# RasbperryPi register map
File version: 1
Registers are 32-bit, read-write, reset 0x0 unless marked. A register's access mark holds for its fields unless they carry their own. Offsets are from the block's base; [hi:lo] are bit positions; {n}, {i} and the like mark numbered series; 'fields as' and 'values as' point back to an identical list.

## SMI — Derived from smi.h apb_id: 0x534D4958
Base 0x7E600000
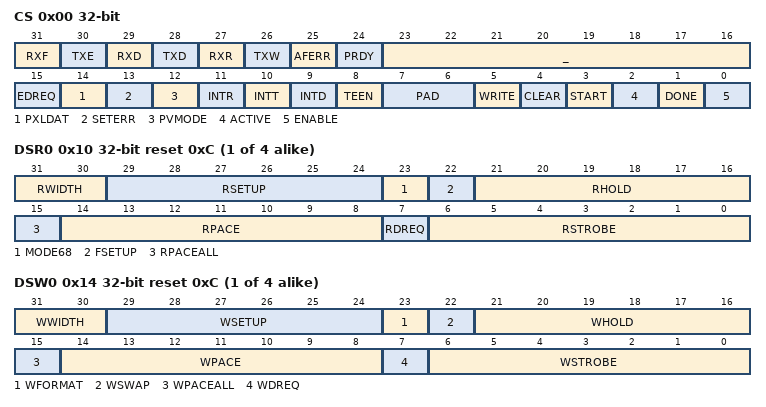
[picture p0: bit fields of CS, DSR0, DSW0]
0x00 CS reset not defined
  [31] RXF, [30] TXE, [29] RXD, [28] TXD, [27] RXR, [26] TXW, [25] AFERR, [24] PRDY, [23:16] _, [15] EDREQ, [14] PXLDAT, [13] SETERR, [12] PVMODE, [11] INTR, [10] INTT, [9] INTD, [8] TEEN, [7:6] PAD, [5] WRITE, [4] CLEAR, [3] START, [2] ACTIVE, [1] DONE, [0] ENABLE
0x04 L
  [31:0] data
0x08 A 10-bit
  [9:8] DEVICE, [7:6] _, [5:0] ADDR
0x0C D
  [31:0] data
{0x10+8i} DSR{i} reset 0xC (i=0..3)
  [31:30] RWIDTH, [29:24] RSETUP, [23] MODE68, [22] FSETUP, [21:16] RHOLD, [15] RPACEALL, [14:8] RPACE, [7] RDREQ, [6:0] RSTROBE
{0x14+8i} DSW{i} reset 0xC (i=0..3)
  [31:30] WWIDTH, [29:24] WSETUP, [23] WFORMAT, [22] WSWAP, [21:16] WHOLD, [15] WPACEALL, [14:8] WPACE, [7] WDREQ, [6:0] WSTROBE
0x30 DC 29-bit reset 0x20
  [28] DMAEN, [27:25] _, [24] DMAP, [23:18] PANICR, [17:12] PANICW, [11:6] REQR, [5:0] REQW

## SPI — Derived from spi_master.h
Base 0x7E204000
0x00 CS 21-bit
  [20] RXF, [19] RXR, [18] TXD, [17] RXD, [16] DONE, [15:11] _, [10] INTR, [9] INTD, [8] DMAEN, [7] TA, [6] CSPOL, [5:4] CLEAR, [3] CPOL, [2] CPHA, [1:0] _
0x04 FIFO 8-bit
  [7:0] DATA
0x08 CLK 16-bit
  [15:0] CDIV
0x0C DLEN 16-bit
  [15:0] LEN
0x10 LTOH 4-bit reset 0x1
  [3:0] TOH

## SYSAC — Derived from system_arbiter_ctrl.h apb_id: 0x4152424D
Base 0x7E009000
0x00 HOST_PRIORITY 4-bit
0x04 DBG_PRIORITY 4-bit
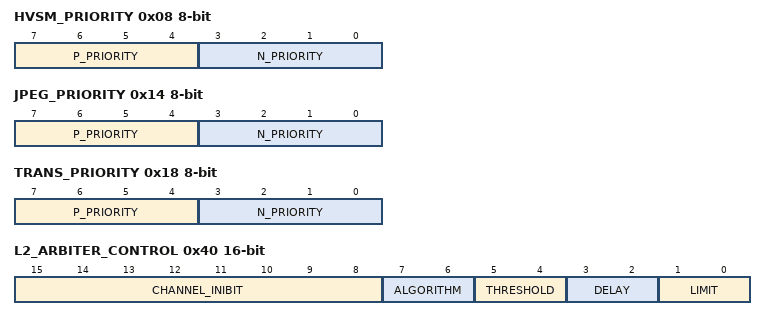
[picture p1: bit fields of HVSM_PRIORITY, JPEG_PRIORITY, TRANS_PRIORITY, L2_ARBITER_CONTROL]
0x08 HVSM_PRIORITY 8-bit
  [7:4] P_PRIORITY, [3:0] N_PRIORITY
0x0C V3D_PRIORITY 4-bit
0x10 H264_PRIORITY 4-bit
0x14 JPEG_PRIORITY 8-bit
  [7:4] P_PRIORITY, [3:0] N_PRIORITY
0x18 TRANS_PRIORITY 8-bit
  [7:4] P_PRIORITY, [3:0] N_PRIORITY
0x1C ISP_PRIORITY 4-bit
0x20 USB_PRIORITY 4-bit
0x40 L2_ARBITER_CONTROL 16-bit
  [15:8] CHANNEL_INIBIT, [7:6] ALGORITHM, [5:4] THRESHOLD, [3:2] DELAY, [1:0] LIMIT
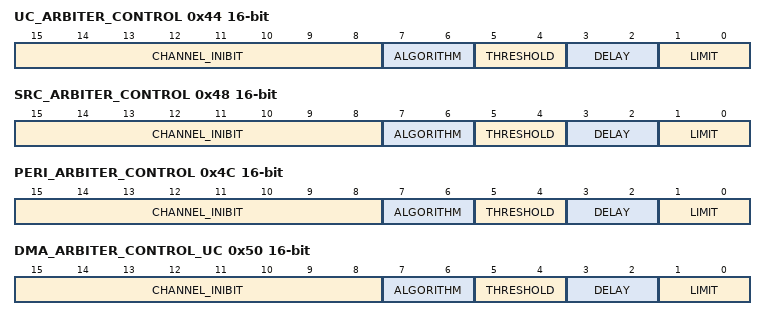
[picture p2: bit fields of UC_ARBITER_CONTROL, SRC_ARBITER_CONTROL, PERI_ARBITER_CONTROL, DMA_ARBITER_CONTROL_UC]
0x44 UC_ARBITER_CONTROL 16-bit
  fields as L2_ARBITER_CONTROL
0x48 SRC_ARBITER_CONTROL 16-bit
  fields as L2_ARBITER_CONTROL
0x4C PERI_ARBITER_CONTROL 16-bit
  fields as L2_ARBITER_CONTROL
0x50 DMA_ARBITER_CONTROL_UC 16-bit
  fields as L2_ARBITER_CONTROL
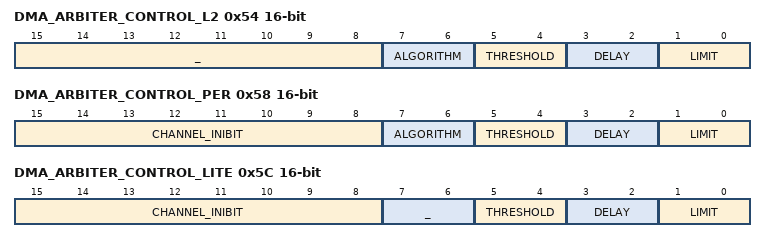
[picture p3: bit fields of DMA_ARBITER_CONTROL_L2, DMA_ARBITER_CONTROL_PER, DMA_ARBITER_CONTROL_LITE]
0x54 DMA_ARBITER_CONTROL_L2 16-bit
  [15:8] _, [7:6] ALGORITHM, [5:4] THRESHOLD, [3:2] DELAY, [1:0] LIMIT
0x58 DMA_ARBITER_CONTROL_PER 16-bit
  fields as L2_ARBITER_CONTROL
0x5C DMA_ARBITER_CONTROL_LITE 16-bit
  [15:8] CHANNEL_INIBIT, [7:6] _, [5:4] THRESHOLD, [3:2] DELAY, [1:0] LIMIT
0x60 DUMMY_STATUS 1-bit
  [0] IDLE
0x64 DMA_DREQ_CONTROL 4-bit
  [3] DMA_DBG_PAUSE_OR, [2:0] SMI_DISABLE
0x68 V3D_LIMITER 12-bit
  [11:8] _, [7:3] MAX_PRIORITY, [3:1] SPARE, [0] ENABLE, [0] INCREMENT, [0] HOLDOFF

## TE — Derived from tectl.h apb_id: 0x00746563
Base 0x7E20E000
{0x0+0xC*i} {i}C reset not defined (i=0..2)
  [31:0] data
{0x4+0xC*i} {i}VSWIDTH reset not defined (i=0..2)
  [31:0] data
{0x8+0xC*i} {i}TIMER reset not defined (i=0..2)
  [31:0] data
